# nrf54ls05b_enga_application register map
Vendor: Nordic Semiconductor; Series: nrf54l; File version: 1
CPU: CM33 r0p4, little endian, MPU, no FPU, 3 interrupt priority bits, 270 interrupts
Registers are 32-bit, read-write, reset 0x0 unless marked. A register's access mark holds for its fields unless they carry their own. Offsets are from the block's base; [hi:lo] are bit positions; lines under a group give offsets from that group; {n}, {i} and the like mark numbered series; 'fields as' and 'values as' point back to an identical list.

## GLOBAL_P1 — GPIO Port 0
Base 0x400D8200
Same registers: GLOBAL_P0 0x4010A000
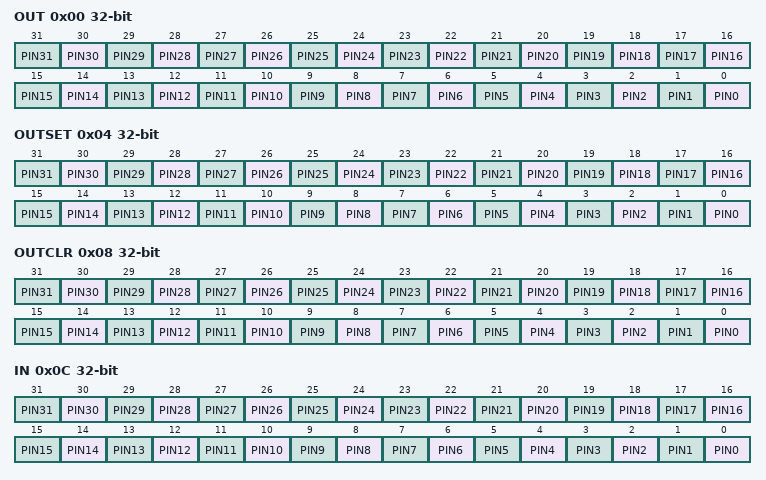
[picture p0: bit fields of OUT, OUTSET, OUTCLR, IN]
0x00 OUT — Write GPIO port
  [all] fields
    0=Low (Pin driver is low); 1=High (Pin driver is high)
  [n] PIN{n} (n=0..31)
0x04 OUTSET write-1-sets — Set individual bits in GPIO port
  [all] fields
    on read: 0=Low (Read: pin driver is low); 1=High (Read: pin driver is high) | on write: 1=Set (Write: writing a '1' sets the pin high; writing a '0' has no effect)
  [n] PIN{n} (n=0..31)
0x08 OUTCLR write-1-clears — Clear individual bits in GPIO port
  [all] fields
    on read: 0=Low (Read: pin driver is low); 1=High (Read: pin driver is high) | on write: 1=Clear (Write: writing a '1' sets the pin low; writing a '0' has no effect)
  [n] PIN{n} (n=0..31)
0x0C IN ro — Read GPIO port
  [all] fields
    0=Low (Pin input is low); 1=High (Pin input is high)
  [n] PIN{n} (n=0..31)
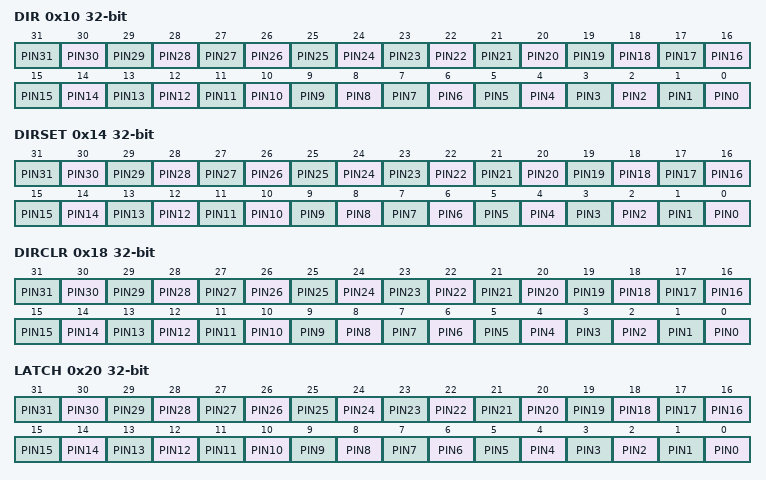
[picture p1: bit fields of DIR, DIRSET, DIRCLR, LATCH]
0x10 DIR — Direction of GPIO pins
  [all] fields
    0=Input (Pin set as input); 1=Output (Pin set as output)
  [n] PIN{n} (n=0..31)
0x14 DIRSET write-1-sets
  [all] fields
    on read: 0=Input (Read: pin set as input); 1=Output (Read: pin set as output) | on write: 1=Set (Write: writing a '1' sets pin to output; writing a '0' has no effect)
  [n] PIN{n} (n=0..31) — Set as output pin {n}
0x18 DIRCLR write-1-clears — DIR clear register
  [all] fields
    on read: 0=Input (Read: pin set as input); 1=Output (Read: pin set as output) | on write: 1=Clear (Write: writing a '1' sets pin to input; writing a '0' has no effect)
  [n] PIN{n} (n=0..31) — Set as input pin {n}
0x20 LATCH — Latch register indicating what GPIO pins that have met the criteria set in the PIN_CNF[n].SENSE registers
  [all] fields
    0=NotLatched (Criteria has not been met); 1=Latched (Criteria has been met)
  [n] PIN{n} (n=0..31) — Status on whether PIN{n} has met criteria set in PIN_CNF[{n}].SENSE register. Write '1' to clear.
0x24 DETECTMODE — Select between default DETECT signal behavior and LDETECT mode
  [0] DETECTMODE
    0=Default (DETECT directly connected to PIN DETECT signals); 1=LDETECT (Use the latched LDETECT behavior)
0x30 PORTCNF group — Unspecified
  0x00 WEAKPU — Control global weak pull-ups on the selected set of GPIO pins
    [1:0] PULLUP — Control pull-up.
      0=Disabled (Pull-up is disabled.); 1=PU0 (Enable pull-up 0.); 2=PU1 (Enable pull-up 1.); 3=PU2 (Enable pull-up 2.)
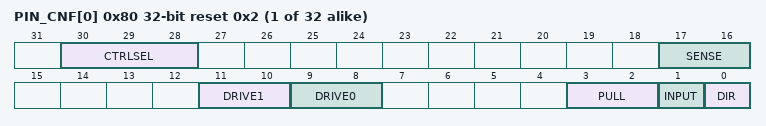
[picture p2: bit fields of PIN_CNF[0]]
{0x80+4i} PIN_CNF[{i}] (i=0..31) reset 0x2 — Description collection: Pin n configuration of GPIO pin
  [30:28] CTRLSEL — Select which module has direct control over this pin
    0=GPIO (GPIO or peripherals with PSEL registers); 1=VPR (VPR processor); 4=GRTC (GRTC peripheral)
  [17:16] SENSE — Pin sensing mechanism
    0=Disabled; 2=High (Sense for high level); 3=Low (Sense for low level)
  [11:10] DRIVE1 — Drive configuration for '1'
    0=S1 (Standard '1'); 1=H1 (High drive '1'); 2=D1 (Disconnect '1'(normally used for wired-or connections)); 3=E1 (Extra high drive '1')
  [9:8] DRIVE0 — Drive configuration for '0'
    0=S0 (Standard '0'); 1=H0 (High drive '0'); 2=D0 (Disconnect '0'(normally used for wired-or connections)); 3=E0 (Extra high drive '0')
  [3:2] PULL — Pull configuration
    0=Disabled (No pull); 1=Pull down on pin; 3=Pull up on pin
  [1] INPUT — Connect or disconnect input buffer
    0=Connect input buffer; 1=Disconnect input buffer
  [0] DIR — Pin direction. Same physical register as DIR register
    0=Input (Configure pin as an input pin); 1=Output (Configure pin as an output pin)

## GLOBAL_WDT30 — Watchdog Timer
Base 0x40108000
0x00 TASKS_START wo — Start WDT
  [0] TASKS_START
    1=Trigger task
0x04 TASKS_STOP wo — Stop WDT
  [0] TASKS_STOP
    1=Trigger task
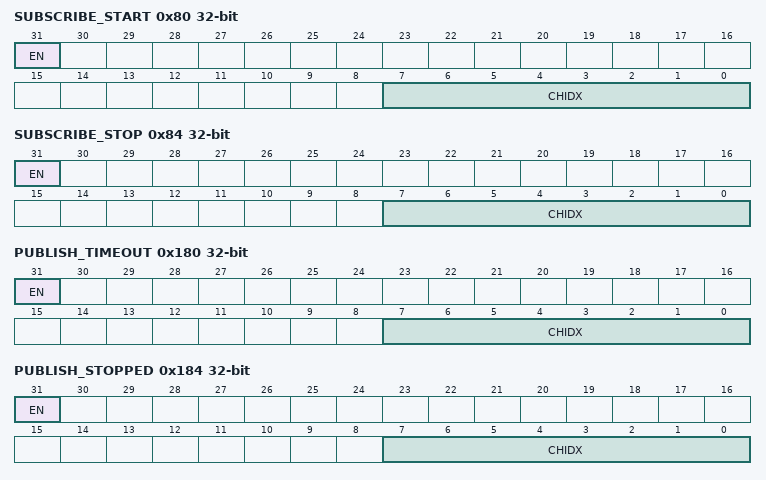
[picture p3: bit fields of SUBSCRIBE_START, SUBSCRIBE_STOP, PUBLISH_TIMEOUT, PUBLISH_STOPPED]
0x80 SUBSCRIBE_START — Subscribe configuration for task START
  [31] EN
    0=Disabled (Disable subscription); 1=Enabled (Enable subscription)
  [7:0] CHIDX — DPPI channel that task START will subscribe to
0x84 SUBSCRIBE_STOP — Subscribe configuration for task STOP
  [31] EN
    values as SUBSCRIBE_START.EN
  [7:0] CHIDX — DPPI channel that task STOP will subscribe to
0x100 EVENTS_TIMEOUT — Watchdog timeout
  [0] EVENTS_TIMEOUT
    0=NotGenerated (Event not generated); 1=Generated (Event generated)
0x104 EVENTS_STOPPED — Watchdog stopped
  [0] EVENTS_STOPPED
    values as EVENTS_TIMEOUT.EVENTS_TIMEOUT
0x180 PUBLISH_TIMEOUT — Publish configuration for event TIMEOUT
  [31] EN
    0=Disabled (Disable publishing); 1=Enabled (Enable publishing)
  [7:0] CHIDX — DPPI channel that event TIMEOUT will publish to
0x184 PUBLISH_STOPPED — Publish configuration for event STOPPED
  [31] EN
    values as PUBLISH_TIMEOUT.EN
  [7:0] CHIDX — DPPI channel that event STOPPED will publish to
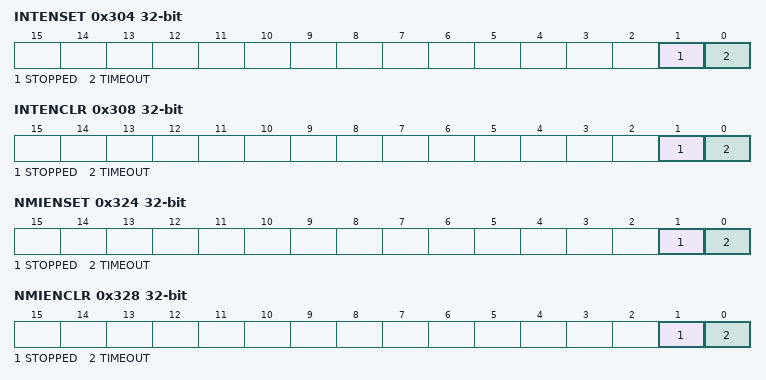
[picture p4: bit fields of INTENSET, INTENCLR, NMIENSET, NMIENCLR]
0x304 INTENSET — Enable interrupt
  [1] STOPPED write-1-sets — Write '1' to enable interrupt for event STOPPED
    on read: 0=Disabled (Read: Disabled); 1=Enabled (Read: Enabled) | on write: 1=Set (Enable)
  [0] TIMEOUT write-1-sets — Write '1' to enable interrupt for event TIMEOUT
    values as STOPPED
0x308 INTENCLR — Disable interrupt
  [1] STOPPED write-1-clears — Write '1' to disable interrupt for event STOPPED
    on read: 0=Disabled (Read: Disabled); 1=Enabled (Read: Enabled) | on write: 1=Clear (Disable)
  [0] TIMEOUT write-1-clears — Write '1' to disable interrupt for event TIMEOUT
    values as STOPPED
0x324 NMIENSET — Enable interrupt
  fields as INTENSET
0x328 NMIENCLR — Disable interrupt
  fields as INTENCLR
0x400 RUNSTATUS ro
  [0] RUNSTATUSWDT — Indicates whether or not WDT is running
    0=NotRunning (Watchdog is not running); 1=Running (Watchdog is running)
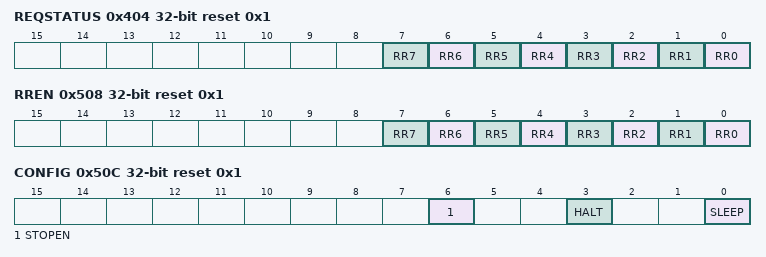
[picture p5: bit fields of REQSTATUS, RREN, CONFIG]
0x404 REQSTATUS ro reset 0x1 — Request status
  [n] RR{n} (n=0..7) — Request status for RR[{n}] register
    0=DisabledOrRequested (RR[{n}] register is not enabled, or are already requesting reload); 1=EnabledAndUnrequested (RR[{n}] register is enabled, and are not yet requesting reload)
0x504 CRV reset 0xFFFFFFFF — Counter reload value
  [31:0] CRV — Counter reload value in number of cycles of the 32.768 kHz clock
0x508 RREN reset 0x1 — Enable register for reload request registers
  [n] RR{n} (n=0..7) — Enable or disable RR[{n}] register
    0=Disabled (Disable RR[{n}] register); 1=Enabled (Enable RR[{n}] register)
0x50C CONFIG reset 0x1 — Configuration register
  [6] STOPEN — Allow stopping WDT
    0=Disable (Do not allow stopping WDT); 1=Enable (Allow stopping WDT)
  [3] HALT — Configure WDT to either be paused, or kept running, while the CPU is halted by the debugger
    0=Pause WDT while the CPU is halted by the debugger; 1=Run (Keep WDT running while the CPU is halted by the debugger)
  [0] SLEEP — Configure WDT to either be paused, or kept running, while the CPU is sleeping
    0=Pause WDT while the CPU is sleeping; 1=Run (Keep WDT running while the CPU is sleeping)
0x520 TSEN wo — Task stop enable
  [31:0] TSEN — Allow stopping WDT
    0x6E524635=Enable (Value to allow stopping WDT)
{0x600+4i} RR[{i}] (i=0..7) wo — Description collection: Reload request n
  [31:0] RR — Reload request register
    0x6E524635=Reload (Value to request a reload of the watchdog timer)
